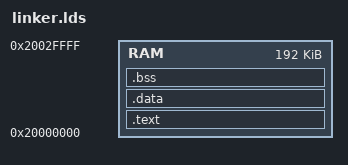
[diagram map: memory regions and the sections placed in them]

ENTRY(_start)

MEMORY
{
        RAM : ORIGIN = 0x20000000, LENGTH = 0x30000
}

SECTIONS
{
        /**********************************************************************
         *                                                                    *
         **********************************************************************/
        .text :
        {
                _stext = .;
                *(.startup)
                *(.text)
                *(.text.*)
                *(.rodata)
                *(.rodata.*)
                . = ALIGN(0x10);
                _etext = .;
        } > RAM
        /**********************************************************************
         *                                                                    *
         **********************************************************************/
        .data :
        {
                _sdata = .;
                *(.data)
                *(.data.*)
                . = ALIGN(0x10);
                _edata = .;
        } > RAM
        /**********************************************************************
         *                                                                    *
         **********************************************************************/
        .bss ADDR(.data) + SIZEOF(.data) (NOLOAD) :
        {
                _sbss = .;
                *(.bss)
                *(.bss.*)
                *(COMMON)
                . = ALIGN(0x10);
                _ebss = .;
        } > RAM
        /**********************************************************************
         *                                                                    *
         **********************************************************************/
        /DISCARD/ :
        {
                *(.comment)
                *(.ARM.exidx*)
                *(.ARM.extab*)
        }
}

